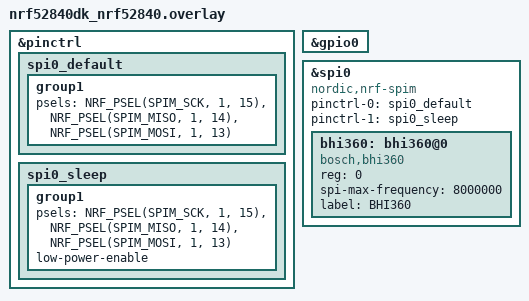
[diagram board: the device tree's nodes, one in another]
&pinctrl {
    spi0_default: spi0_default {
        group1 {
            psels = <NRF_PSEL(SPIM_SCK, 1, 15)>,
				<NRF_PSEL(SPIM_MISO, 1, 14)>,
				<NRF_PSEL(SPIM_MOSI, 1, 13)>;
        };
    };

    spi0_sleep: spi0_sleep {
        group1 {
            psels = <NRF_PSEL(SPIM_SCK, 1, 15)>,
				<NRF_PSEL(SPIM_MISO, 1, 14)>,
				<NRF_PSEL(SPIM_MOSI, 1, 13)>;
            low-power-enable;
        };
    };
};

&gpio0 {
    status = "okay";
};

&spi0 {
    compatible = "nordic,nrf-spim";
    status = "okay";
    pinctrl-0 = <&spi0_default>;
    pinctrl-1 = <&spi0_sleep>;
    pinctrl-names = "default", "sleep";

    bhi360: bhi360@0 {
        compatible = "bosch,bhi360";
        reg = <0>;
        status = "okay";
        spi-max-frequency = <8000000>;
        label = "BHI360";
    };
}; 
